# HDSC_HC32L130F8UA register map
Vendor: HDSC Co.Ltd; Series: ARMCM0P; File version: 1.2
CPU: CM0 r0p0, little endian, no MPU, no FPU, 3 interrupt priority bits
Registers are 32-bit, read-write, reset 0x0 unless marked. A register's access mark holds for its fields unless they carry their own. Offsets are from the block's base; lines under a group give offsets from that group; [hi:lo] are bit positions; {n}, {i} and the like mark numbered series; 'fields as' and 'values as' point back to an identical list; <NAME> marks a mode.

## Memory map
0x40000000 UART0 size 0x1C — desc UART
0x40000100 UART1 size 0x1C — desc UART
0x40000200 LPUART0 size 0x1C — desc LPUART
0x40000400 I2C0 size 0x18 — desc I2C
0x40000800 SPI0 size 0x18 — desc SPI
0x40000C00 TIM0_MODE0 size 0x34
0x40000C00 TIM0_MODE1 size 0x40
0x40000C00 TIM0_MODE23 size 0x44
0x40000D00 TIM1_MODE0 size 0x34
0x40000D00 TIM1_MODE1 size 0x40
0x40000D00 TIM1_MODE23 size 0x44
0x40000E00 TIM2_MODE0 size 0x34
0x40000E00 TIM2_MODE1 size 0x40
0x40000E00 TIM2_MODE23 size 0x44
0x40000F00 LPTIMER size 0x18
0x40000F00 WDT size 0x88
0x40001000 PCA size 0x6C
0x40001400 RTC size 0x34
0x40001800 CLK_TRIM size 0x1C
0x40002000 SYSCTRL size 0x40
0x4000201C RESET size 0x10
0x40002400 ADC size 0xCC
0x40002400 BGR size 0x4
0x40002400 LVD size 0x30
0x40002400 VC size 0x28
0x40002438 DEBUG_ACTIVE size 0x4
0x40003000 TIM4 size 0x400
0x40003400 TIM5 size 0x400
0x40003800 TIM6 size 0x400
0x40004400 I2C1 size 0x18 — desc I2C
0x40004C00 RNG size 0x14
0x40005400 PCNT size 0x31
0x40005800 TIM3_MODE0 size 0x34
0x40005800 TIM3_MODE1 size 0x40
0x40005800 TIM3_MODE23 size 0x54
0x40020000 FLASH size 0x34
0x40020400 RAM size 0x10
0x40020900 CRC size 0x100
0x40020C00 GPIO size 0x800
0x40021000 DMAC size 0x30
0x40021400 AES size 0x30
0x40021800 HDIV size 0x18

## ADC
Base 0x40002400
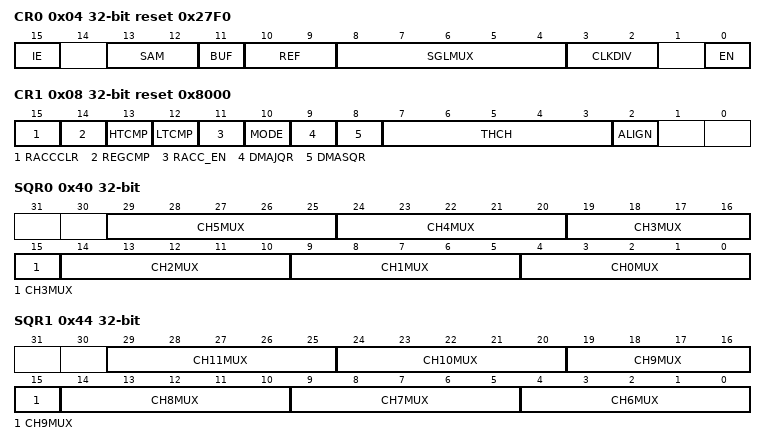
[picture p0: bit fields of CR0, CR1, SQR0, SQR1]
0x04 CR0 reset 0x27F0
  [15] IE, [13:12] SAM, [11] BUF, [10:9] REF, [8:4] SGLMUX, [3:2] CLKDIV, [0] EN
0x08 CR1 reset 0x8000
  [15] RACCCLR, [14] REGCMP, [13] HTCMP, [12] LTCMP, [11] RACC_EN, [10] MODE, [9] DMAJQR, [8] DMASQR, [7:3] THCH, [2] ALIGN
0x40 SQR0
  [5n+4:5n] CH{n}MUX (n=0..5)
0x44 SQR1
  [5n-26:5n-30] CH{n}MUX (n=6..11)
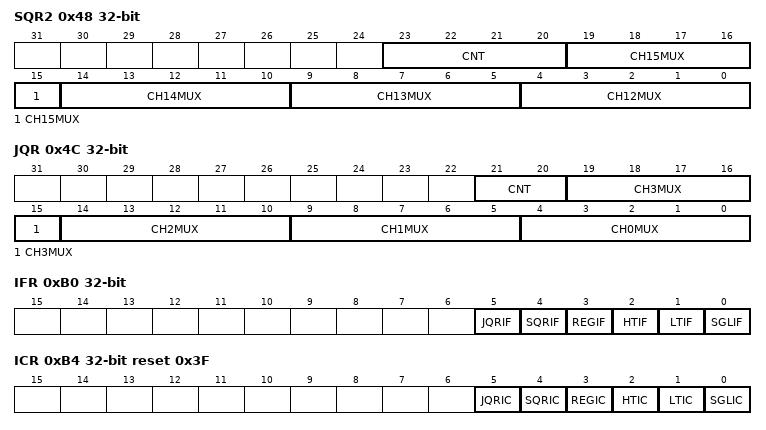
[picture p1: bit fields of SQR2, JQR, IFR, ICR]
0x48 SQR2
  [23:20] CNT, [5n-56:5n-60] CH{n}MUX (n=12..15)
0x4C JQR
  [21:20] CNT, [5n+4:5n] CH{n}MUX (n=0..3)
{0x50+4i} SQRRESULT{i} ro (i=0..12)
  [11:0] RESULT
0x84 SQR_RESULT13 ro
  [11:0] RESULT
0x88 SQRRESULT14 ro
  [11:0] RESULT
0x8C SQRRESULT15 ro
  [11:0] RESULT
{0x90+4i} JQRRESULT{i} ro (i=0..3)
  [11:0] RESULT
0xA0 RESULT ro
  [11:0] RESULT
0xA4 RESULTACC ro
  [19:0] RESULTACC
0xA8 HT reset 0xFFF
  [11:0] HT
0xAC LT
  [11:0] LT
0xB0 IFR ro
  [5] JQRIF, [4] SQRIF, [3] REGIF, [2] HTIF, [1] LTIF, [0] SGLIF
0xB4 ICR wo reset 0x3F
  [5] JQRIC, [4] SQRIC, [3] REGIC, [2] HTIC, [1] LTIC, [0] SGLIC
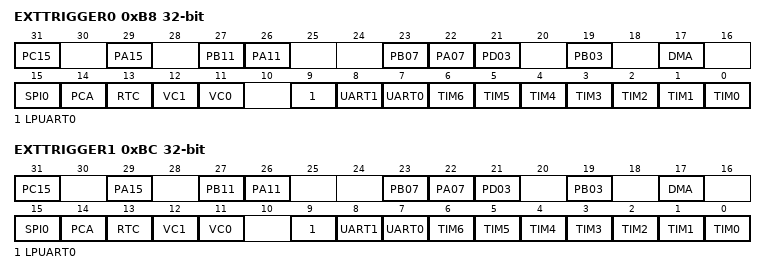
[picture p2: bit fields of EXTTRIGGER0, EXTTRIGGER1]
0xB8 EXTTRIGGER0
  [31] PC15, [29] PA15, [27] PB11, [26] PA11, [23] PB07, [22] PA07, [21] PD03, [19] PB03, [17] DMA, [15] SPI0, [14] PCA, [13] RTC, [12] VC1, [11] VC0, [9] LPUART0, [8] UART1, [7] UART0, [n] TIM{n} (n=0..6)
0xBC EXTTRIGGER1
  fields as EXTTRIGGER0
0xC0 SGLSTART
  [0] START
0xC4 SQRSTART
  [0] START
0xC8 JQRSTART
  [0] START

## AES
Base 0x40021400
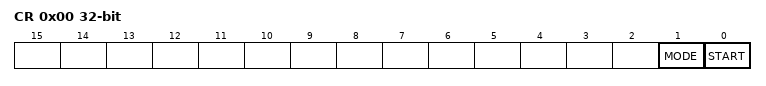
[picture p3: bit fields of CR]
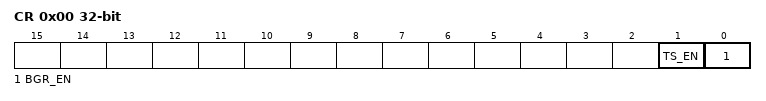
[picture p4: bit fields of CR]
0x00 CR
  [1] MODE, [0] START
0x10 DATA0
{0x10+4i} DATA{i} (i=1..3)
  [31:0] DATA0
0x20 KEY0
{0x20+4i} KEY{i} (i=1..3)
  [31:0] KEY0

## BGR
Base 0x40002400; alternate view of ADC
0x00 CR
  [1] TS_EN, [0] BGR_EN

## CLK_TRIM
Base 0x40001800
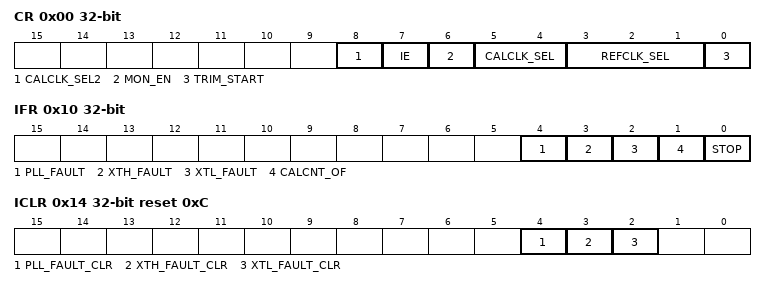
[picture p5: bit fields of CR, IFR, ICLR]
0x00 CR (reset mask 0xFF)
  [8] CALCLK_SEL2, [7] IE, [6] MON_EN, [5:4] CALCLK_SEL, [3:1] REFCLK_SEL, [0] TRIM_START
0x04 REFCON
  [31:0] RCNTVAL
0x08 REFCNT ro
0x0C CALCNT ro
0x10 IFR ro (reset mask 0xF)
  [4] PLL_FAULT, [3] XTH_FAULT, [2] XTL_FAULT, [1] CALCNT_OF, [0] STOP
0x14 ICLR reset 0xC (reset mask 0xC)
  [4] PLL_FAULT_CLR, [3] XTH_FAULT_CLR, [2] XTL_FAULT_CLR
0x18 CALCON reset 0xFFFFFFFF
  [31:0] CCNTVAL

## CRC
Base 0x40020900
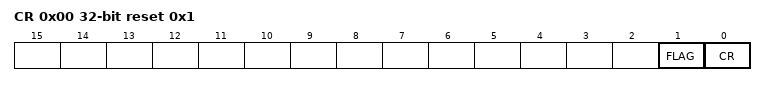
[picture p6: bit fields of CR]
0x00 CR reset 0x1
  [1] FLAG ro, [0] CR
0x04 RESULT
0x80 DATA wo

## DEBUG_ACTIVE
Base 0x40002438
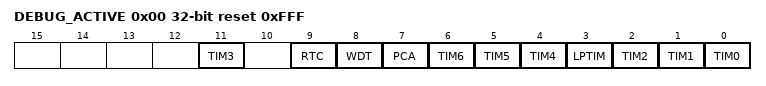
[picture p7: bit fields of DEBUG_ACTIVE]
0x00 DEBUG_ACTIVE reset 0xFFF
  [11] TIM3, [9] RTC, [8] WDT, [7] PCA, [6] TIM6, [5] TIM5, [4] TIM4, [3] LPTIM, [2] TIM2, [1] TIM1, [0] TIM0
